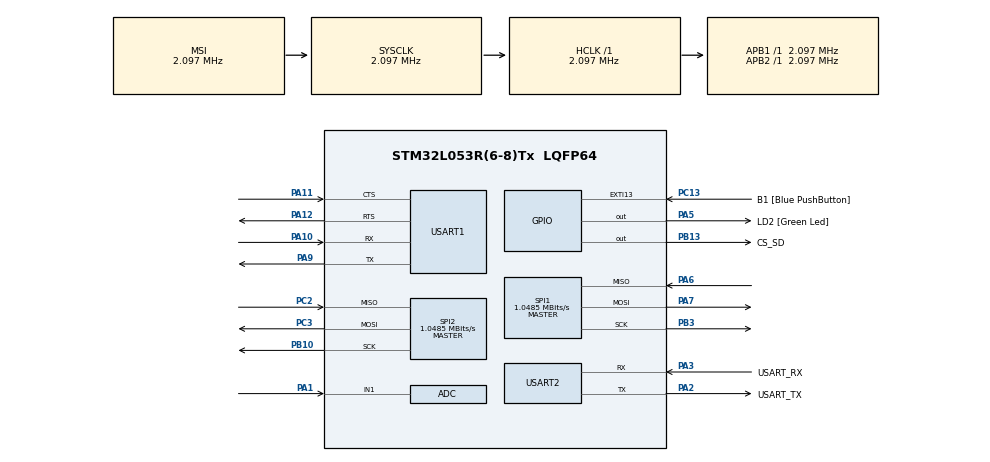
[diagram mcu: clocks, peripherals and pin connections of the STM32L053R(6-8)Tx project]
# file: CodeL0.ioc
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Mcu.Family=STM32L0
Mcu.Name=STM32L053R(6-8)Tx
Mcu.Package=LQFP64
PA0.Mode=SYS_WakeUp0
PA0.Signal=SYS_WKUP1
PA1.Mode=IN1
PA1.Signal=ADC_IN1
PA10.Mode=Asynchronous
PA10.Signal=USART1_RX
PA11.Mode=CTS_RTS
PA11.Signal=USART1_CTS
PA12.Mode=CTS_RTS
PA12.Signal=USART1_RTS
PA13.GPIO_Label=TMS
PA13.Signal=SYS_SWDIO
PA14.GPIO_Label=TCK
PA14.Signal=SYS_SWCLK
PA2.GPIO_Label=USART_TX
PA2.Mode=Asynchronous
PA2.Signal=USART2_TX
PA3.GPIO_Label=USART_RX
PA3.Mode=Asynchronous
PA3.Signal=USART2_RX
PA5.GPIO_Label=LD2 [Green Led]
PA5.Signal=GPIO_Output
PA6.Mode=Full_Duplex_Master
PA6.Signal=SPI1_MISO
PA7.Mode=Full_Duplex_Master
PA7.Signal=SPI1_MOSI
PA9.Mode=Asynchronous
PA9.Signal=USART1_TX
PB10.Mode=Full_Duplex_Master
PB10.Signal=SPI2_SCK
PB13.GPIO_Label=CS_SD
PB13.Signal=GPIO_Output
PB3.Mode=Full_Duplex_Master
PB3.Signal=SPI1_SCK
PC13.GPIO_Label=B1 [Blue PushButton]
PC13.GPIO_ModeDefaultEXTI=GPIO_MODE_IT_FALLING
PC13.Signal=GPXTI13
PC14-OSC32_IN.Mode=LSE-External-Oscillator
PC14-OSC32_IN.Signal=RCC_OSC32_IN
PC15-OSC32_OUT.Mode=LSE-External-Oscillator
PC15-OSC32_OUT.Signal=RCC_OSC32_OUT
PC2.Mode=Full_Duplex_Master
PC2.Signal=SPI2_MISO
PC3.Mode=Full_Duplex_Master
PC3.Signal=SPI2_MOSI
PH0-OSC_IN.Mode=HSE-External-Oscillator
PH0-OSC_IN.Signal=RCC_OSC_IN
PH1-OSC_OUT.Mode=HSE-External-Oscillator
PH1-OSC_OUT.Signal=RCC_OSC_OUT
ProjectManager.HeapSize=0x200
ProjectManager.StackSize=0x400
ProjectManager.TargetToolchain=MDK-ARM V5.32
RCC.AHBFreq_Value=2097000
RCC.APB1Freq_Value=2097000
RCC.APB1TimFreq_Value=2097000
RCC.APB2Freq_Value=2097000
RCC.APB2TimFreq_Value=2097000
RCC.HSE_VALUE=8000000
RCC.HSI16_VALUE=16000000
RCC.HSI48_VALUE=48000000
RCC.HSI_VALUE=16000000
RCC.MSI_VALUE=2097000
RCC.SYSCLKFreq_VALUE=2097000
RCC.VCOOutputFreq_Value=48000000
SPI1.CalculateBaudRate=1.0485 MBits/s
SPI1.Direction=SPI_DIRECTION_2LINES
SPI1.Mode=SPI_MODE_MASTER
SPI1.VirtualType=VM_MASTER
SPI2.CalculateBaudRate=1.0485 MBits/s
SPI2.Direction=SPI_DIRECTION_2LINES
SPI2.Mode=SPI_MODE_MASTER
SPI2.VirtualType=VM_MASTER
USART1.VirtualMode-Asynchronous=VM_ASYNC
USART2.VirtualMode-Asynchronous=VM_ASYNC
VP_RTC_VS_RTC_Activate.Mode=RTC_Enabled
VP_RTC_VS_RTC_Calendar.Mode=RTC_Calendar
board=NUCLEO-L053R8

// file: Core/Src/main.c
/* USER CODE BEGIN Header */
/**
  ******************************************************************************
  * @file           : main.c
  * @brief          : Main program body
  ******************************************************************************
  * @attention
  *
  * <h2><center>&copy; Copyright (c) 2021 STMicroelectronics.
  * All rights reserved.</center></h2>
  *
  * This software component is licensed by ST under BSD 3-Clause license,
  * the "License"; You may not use this file except in compliance with the
  * License. You may obtain a copy of the License at:
  *                        opensource.org/licenses/BSD-3-Clause
  *
  ******************************************************************************
  */
/* USER CODE END Header */
#include "main.h"

ADC_HandleTypeDef hadc;

RTC_HandleTypeDef hrtc;

SPI_HandleTypeDef hspi1;
SPI_HandleTypeDef hspi2;

UART_HandleTypeDef huart1;
UART_HandleTypeDef huart2;

/* USER CODE BEGIN PV */
uint8_t txbuf[100];
uint8_t rxbuf[100];

/* USER CODE END PV */

void SystemClock_Config(void);
static void MX_GPIO_Init(void);
static void MX_ADC_Init(void);
static void MX_RTC_Init(void);
static void MX_SPI1_Init(void);
static void MX_USART1_UART_Init(void);
static void MX_USART2_UART_Init(void);
static void MX_SPI2_Init(void);

int main(void)
{

  /* MCU Configuration--------------------------------------------------------*/

  /* Reset of all peripherals, Initializes the Flash interface and the Systick. */
  HAL_Init();

  /* Configure the system clock */
  SystemClock_Config();

  /* Initialize all configured peripherals */
  MX_GPIO_Init();
  MX_ADC_Init();
  MX_RTC_Init();
  MX_SPI1_Init();
  MX_USART1_UART_Init();
  MX_USART2_UART_Init();
  MX_SPI2_Init();

  /* Infinite loop */
  while (1)
  {

    /* USER CODE BEGIN 3 */
		HAL_GPIO_WritePin(CS_SD_GPIO_Port, CS_SD_Pin, GPIO_PIN_RESET);

		HAL_SPI_TransmitReceive(&hspi2, txbuf, rxbuf, 1, 0xFF);
		HAL_GPIO_WritePin(CS_SD_GPIO_Port, CS_SD_Pin, GPIO_PIN_SET);
		HAL_Delay(500);

  }
  /* USER CODE END 3 */
}

void SystemClock_Config(void)
{
  RCC_OscInitTypeDef RCC_OscInitStruct = {0};
  RCC_ClkInitTypeDef RCC_ClkInitStruct = {0};
  RCC_PeriphCLKInitTypeDef PeriphClkInit = {0};

  /** Configure the main internal regulator output voltage
  */
  __HAL_PWR_VOLTAGESCALING_CONFIG(PWR_REGULATOR_VOLTAGE_SCALE1);
  /** Initializes the RCC Oscillators according to the specified parameters
  * in the RCC_OscInitTypeDef structure.
  */
  RCC_OscInitStruct.OscillatorType = RCC_OSCILLATORTYPE_LSI|RCC_OSCILLATORTYPE_MSI;
  RCC_OscInitStruct.LSIState = RCC_LSI_ON;
  RCC_OscInitStruct.MSIState = RCC_MSI_ON;
  RCC_OscInitStruct.MSICalibrationValue = 0;
  RCC_OscInitStruct.MSIClockRange = RCC_MSIRANGE_5;
  RCC_OscInitStruct.PLL.PLLState = RCC_PLL_NONE;
  if (HAL_RCC_OscConfig(&RCC_OscInitStruct) != HAL_OK)
  {
    Error_Handler();
  }
  /** Initializes the CPU, AHB and APB buses clocks
  */
  RCC_ClkInitStruct.ClockType = RCC_CLOCKTYPE_HCLK|RCC_CLOCKTYPE_SYSCLK
                              |RCC_CLOCKTYPE_PCLK1|RCC_CLOCKTYPE_PCLK2;
  RCC_ClkInitStruct.SYSCLKSource = RCC_SYSCLKSOURCE_MSI;
  RCC_ClkInitStruct.AHBCLKDivider = RCC_SYSCLK_DIV1;
  RCC_ClkInitStruct.APB1CLKDivider = RCC_HCLK_DIV1;
  RCC_ClkInitStruct.APB2CLKDivider = RCC_HCLK_DIV1;

  if (HAL_RCC_ClockConfig(&RCC_ClkInitStruct, FLASH_LATENCY_0) != HAL_OK)
  {
    Error_Handler();
  }
  PeriphClkInit.PeriphClockSelection = RCC_PERIPHCLK_USART1|RCC_PERIPHCLK_USART2
                              |RCC_PERIPHCLK_RTC;
  PeriphClkInit.Usart1ClockSelection = RCC_USART1CLKSOURCE_PCLK2;
  PeriphClkInit.Usart2ClockSelection = RCC_USART2CLKSOURCE_PCLK1;
  PeriphClkInit.RTCClockSelection = RCC_RTCCLKSOURCE_LSI;
  if (HAL_RCCEx_PeriphCLKConfig(&PeriphClkInit) != HAL_OK)
  {
    Error_Handler();
  }
}

static void MX_ADC_Init(void)
{

  ADC_ChannelConfTypeDef sConfig = {0};

  /** Configure the global features of the ADC (Clock, Resolution, Data Alignment and number of conversion)
  */
  hadc.Instance = ADC1;
  hadc.Init.OversamplingMode = DISABLE;
  hadc.Init.ClockPrescaler = ADC_CLOCK_SYNC_PCLK_DIV1;
  hadc.Init.Resolution = ADC_RESOLUTION_12B;
  hadc.Init.SamplingTime = ADC_SAMPLETIME_1CYCLE_5;
  hadc.Init.ScanConvMode = ADC_SCAN_DIRECTION_FORWARD;
  hadc.Init.DataAlign = ADC_DATAALIGN_RIGHT;
  hadc.Init.ContinuousConvMode = DISABLE;
  hadc.Init.DiscontinuousConvMode = DISABLE;
  hadc.Init.ExternalTrigConvEdge = ADC_EXTERNALTRIGCONVEDGE_NONE;
  hadc.Init.ExternalTrigConv = ADC_SOFTWARE_START;
  hadc.Init.DMAContinuousRequests = DISABLE;
  hadc.Init.EOCSelection = ADC_EOC_SINGLE_CONV;
  hadc.Init.Overrun = ADC_OVR_DATA_PRESERVED;
  hadc.Init.LowPowerAutoWait = DISABLE;
  hadc.Init.LowPowerFrequencyMode = ENABLE;
  hadc.Init.LowPowerAutoPowerOff = DISABLE;
  if (HAL_ADC_Init(&hadc) != HAL_OK)
  {
    Error_Handler();
  }
  /** Configure for the selected ADC regular channel to be converted.
  */
  sConfig.Channel = ADC_CHANNEL_1;
  sConfig.Rank = ADC_RANK_CHANNEL_NUMBER;
  if (HAL_ADC_ConfigChannel(&hadc, &sConfig) != HAL_OK)
  {
    Error_Handler();
  }

}

static void MX_RTC_Init(void)
{

  RTC_TimeTypeDef sTime = {0};
  RTC_DateTypeDef sDate = {0};

  /** Initialize RTC Only
  */
  hrtc.Instance = RTC;
  hrtc.Init.HourFormat = RTC_HOURFORMAT_24;
  hrtc.Init.AsynchPrediv = 127;
  hrtc.Init.SynchPrediv = 255;
  hrtc.Init.OutPut = RTC_OUTPUT_DISABLE;
  hrtc.Init.OutPutRemap = RTC_OUTPUT_REMAP_NONE;
  hrtc.Init.OutPutPolarity = RTC_OUTPUT_POLARITY_HIGH;
  hrtc.Init.OutPutType = RTC_OUTPUT_TYPE_OPENDRAIN;
  if (HAL_RTC_Init(&hrtc) != HAL_OK)
  {
    Error_Handler();
  }

  /** Initialize RTC and set the Time and Date
  */
  sTime.Hours = 0x0;
  sTime.Minutes = 0x0;
  sTime.Seconds = 0x0;
  sTime.DayLightSaving = RTC_DAYLIGHTSAVING_NONE;
  sTime.StoreOperation = RTC_STOREOPERATION_RESET;
  if (HAL_RTC_SetTime(&hrtc, &sTime, RTC_FORMAT_BCD) != HAL_OK)
  {
    Error_Handler();
  }
  sDate.WeekDay = RTC_WEEKDAY_MONDAY;
  sDate.Month = RTC_MONTH_JANUARY;
  sDate.Date = 0x1;
  sDate.Year = 0x0;

  if (HAL_RTC_SetDate(&hrtc, &sDate, RTC_FORMAT_BCD) != HAL_OK)
  {
    Error_Handler();
  }

}

static void MX_SPI1_Init(void)
{

  /* SPI1 parameter configuration*/
  hspi1.Instance = SPI1;
  hspi1.Init.Mode = SPI_MODE_MASTER;
  hspi1.Init.Direction = SPI_DIRECTION_2LINES;
  hspi1.Init.DataSize = SPI_DATASIZE_8BIT;
  hspi1.Init.CLKPolarity = SPI_POLARITY_LOW;
  hspi1.Init.CLKPhase = SPI_PHASE_1EDGE;
  hspi1.Init.NSS = SPI_NSS_SOFT;
  hspi1.Init.BaudRatePrescaler = SPI_BAUDRATEPRESCALER_2;
  hspi1.Init.FirstBit = SPI_FIRSTBIT_MSB;
  hspi1.Init.TIMode = SPI_TIMODE_DISABLE;
  hspi1.Init.CRCCalculation = SPI_CRCCALCULATION_DISABLE;
  hspi1.Init.CRCPolynomial = 7;
  if (HAL_SPI_Init(&hspi1) != HAL_OK)
  {
    Error_Handler();
  }

}

static void MX_SPI2_Init(void)
{

  /* SPI2 parameter configuration*/
  hspi2.Instance = SPI2;
  hspi2.Init.Mode = SPI_MODE_MASTER;
  hspi2.Init.Direction = SPI_DIRECTION_2LINES;
  hspi2.Init.DataSize = SPI_DATASIZE_8BIT;
  hspi2.Init.CLKPolarity = SPI_POLARITY_LOW;
  hspi2.Init.CLKPhase = SPI_PHASE_1EDGE;
  hspi2.Init.NSS = SPI_NSS_SOFT;
  hspi2.Init.BaudRatePrescaler = SPI_BAUDRATEPRESCALER_2;
  hspi2.Init.FirstBit = SPI_FIRSTBIT_MSB;
  hspi2.Init.TIMode = SPI_TIMODE_DISABLE;
  hspi2.Init.CRCCalculation = SPI_CRCCALCULATION_DISABLE;
  hspi2.Init.CRCPolynomial = 7;
  if (HAL_SPI_Init(&hspi2) != HAL_OK)
  {
    Error_Handler();
  }

}

static void MX_USART1_UART_Init(void)
{

  huart1.Instance = USART1;
  huart1.Init.BaudRate = 115200;
  huart1.Init.WordLength = UART_WORDLENGTH_8B;
  huart1.Init.StopBits = UART_STOPBITS_1;
  huart1.Init.Parity = UART_PARITY_NONE;
  huart1.Init.Mode = UART_MODE_TX_RX;
  huart1.Init.HwFlowCtl = UART_HWCONTROL_RTS_CTS;
  huart1.Init.OverSampling = UART_OVERSAMPLING_16;
  huart1.Init.OneBitSampling = UART_ONE_BIT_SAMPLE_DISABLE;
  huart1.AdvancedInit.AdvFeatureInit = UART_ADVFEATURE_NO_INIT;
  if (HAL_UART_Init(&huart1) != HAL_OK)
  {
    Error_Handler();
  }

}

static void MX_USART2_UART_Init(void)
{

  huart2.Instance = USART2;
  huart2.Init.BaudRate = 115200;
  huart2.Init.WordLength = UART_WORDLENGTH_8B;
  huart2.Init.StopBits = UART_STOPBITS_1;
  huart2.Init.Parity = UART_PARITY_NONE;
  huart2.Init.Mode = UART_MODE_TX_RX;
  huart2.Init.HwFlowCtl = UART_HWCONTROL_NONE;
  huart2.Init.OverSampling = UART_OVERSAMPLING_16;
  huart2.Init.OneBitSampling = UART_ONE_BIT_SAMPLE_DISABLE;
  huart2.AdvancedInit.AdvFeatureInit = UART_ADVFEATURE_NO_INIT;
  if (HAL_UART_Init(&huart2) != HAL_OK)
  {
    Error_Handler();
  }

}

static void MX_GPIO_Init(void)
{
  GPIO_InitTypeDef GPIO_InitStruct = {0};

  /* GPIO Ports Clock Enable */
  __HAL_RCC_GPIOC_CLK_ENABLE();
  __HAL_RCC_GPIOH_CLK_ENABLE();
  __HAL_RCC_GPIOA_CLK_ENABLE();
  __HAL_RCC_GPIOB_CLK_ENABLE();

  /*Configure GPIO pin Output Level */
  HAL_GPIO_WritePin(LD2_GPIO_Port, LD2_Pin, GPIO_PIN_RESET);

  /*Configure GPIO pin Output Level */
  HAL_GPIO_WritePin(CS_SD_GPIO_Port, CS_SD_Pin, GPIO_PIN_RESET);

  /*Configure GPIO pin : B1_Pin */
  GPIO_InitStruct.Pin = B1_Pin;
  GPIO_InitStruct.Mode = GPIO_MODE_IT_FALLING;
  GPIO_InitStruct.Pull = GPIO_NOPULL;
  HAL_GPIO_Init(B1_GPIO_Port, &GPIO_InitStruct);

  /*Configure GPIO pin : LD2_Pin */
  GPIO_InitStruct.Pin = LD2_Pin;
  GPIO_InitStruct.Mode = GPIO_MODE_OUTPUT_PP;
  GPIO_InitStruct.Pull = GPIO_NOPULL;
  GPIO_InitStruct.Speed = GPIO_SPEED_FREQ_LOW;
  HAL_GPIO_Init(LD2_GPIO_Port, &GPIO_InitStruct);

  /*Configure GPIO pin : CS_SD_Pin */
  GPIO_InitStruct.Pin = CS_SD_Pin;
  GPIO_InitStruct.Mode = GPIO_MODE_OUTPUT_PP;
  GPIO_InitStruct.Pull = GPIO_NOPULL;
  GPIO_InitStruct.Speed = GPIO_SPEED_FREQ_LOW;
  HAL_GPIO_Init(CS_SD_GPIO_Port, &GPIO_InitStruct);

}

void Error_Handler(void)
{
  __disable_irq();
  while (1)
  {
  }
}

/************************ (C) COPYRIGHT STMicroelectronics *****END OF FILE****/
